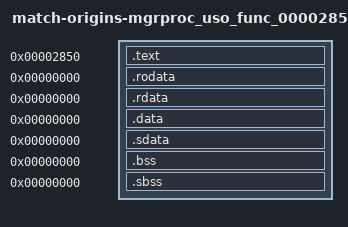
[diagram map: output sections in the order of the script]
/* Standard linker bindings; original USO identity is independently audited. */
SECTIONS {
 .text 0x2850 : SUBALIGN(4) { *(.text) *(.text.*) }
 .rodata 0x0 : SUBALIGN(4) { *(.rodata) *(.rodata.*) }
 .rdata 0x0 : SUBALIGN(4) { *(.rdata) *(.rdata.*) }
 .data 0x0 : SUBALIGN(4) { *(.data) *(.data.*) }
 .sdata 0x0 : SUBALIGN(4) { *(.sdata) *(.sdata.*) }
 .bss 0x0 : SUBALIGN(4) { *(.bss) *(.bss.*) }
 .sbss 0x0 : SUBALIGN(4) { *(.sbss) *(.sbss.*) }
 /DISCARD/ : { *(.mdebug) *(.reginfo) *(.pdr) *(.comment) *(.MIPS.abiflags) *(.options) }
}
import_0024E608 = 0x0;
import_0024F2C8 = 0x0;
import_0024F34C = 0x0;
import_8024CAF8 = 0x0;
